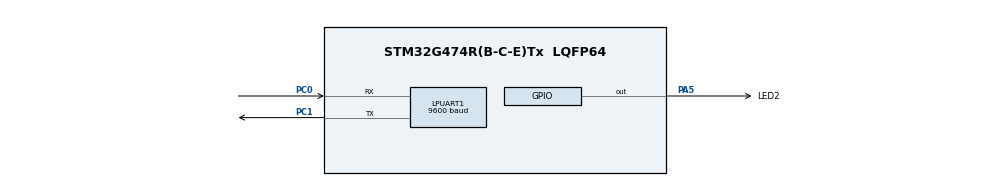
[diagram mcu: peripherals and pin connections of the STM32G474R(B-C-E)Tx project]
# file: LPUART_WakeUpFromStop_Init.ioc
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LPUART1.BaudRate=9600
LPUART1.ClockPrescaler=UART_PRESCALER_DIV1
LPUART1.DMADisableonRxErrorParam=UART_ADVFEATURE_DMA_ENABLEONRXERROR
LPUART1.DataInvertParam=UART_ADVFEATURE_DATAINV_DISABLE
LPUART1.FIFOMode=UART_FIFOMODE_DISABLE
LPUART1.MSBFirstParam=UART_ADVFEATURE_MSBFIRST_DISABLE
LPUART1.Mode=UART_MODE_TX_RX
LPUART1.OneBitSampling=UART_ONE_BIT_SAMPLE_DISABLE
LPUART1.OverrunDisableParam=UART_ADVFEATURE_OVERRUN_ENABLE
LPUART1.Parity=UART_PARITY_NONE
LPUART1.RXFIFOThreshold=UART_RXFIFO_THRESHOLD_1_8
LPUART1.RxPinLevelInvertParam=UART_ADVFEATURE_RXINV_DISABLE
LPUART1.StopBits=UART_STOPBITS_1
LPUART1.SwapParam=UART_ADVFEATURE_SWAP_DISABLE
LPUART1.TXFIFOThreshold=UART_TXFIFO_THRESHOLD_1_8
LPUART1.TxPinLevelInvertParam=UART_ADVFEATURE_TXINV_DISABLE
LPUART1.WordLength=UART_WORDLENGTH_8B
Mcu.Family=STM32G4
Mcu.Name=STM32G474R(B-C-E)Tx
Mcu.Package=LQFP64
NVIC.LPUART1_IRQn=true\:0\:0\:false\:false\:true\:true\:true\:true
NVIC.PriorityGroup=NVIC_PRIORITYGROUP_4
PA5.GPIO_Label=LED2
PA5.Signal=GPIO_Output
PC0.GPIO_Speed=GPIO_SPEED_FREQ_HIGH
PC0.Mode=Asynchronous
PC0.Signal=LPUART1_RX
PC1.GPIO_Speed=GPIO_SPEED_FREQ_HIGH
PC1.Mode=Asynchronous
PC1.Signal=LPUART1_TX
ProjectManager.HeapSize=0x200
ProjectManager.StackSize=0x400
ProjectManager.TargetToolchain=EWARM V8.32
RCC.ADC12Freq_Value=16000000
RCC.ADC345Freq_Value=16000000
RCC.AHBFreq_Value=16000000
RCC.APB1Freq_Value=16000000
RCC.APB1TimFreq_Value=16000000
RCC.APB2Freq_Value=16000000
RCC.APB2TimFreq_Value=16000000
RCC.CortexFreq_Value=16000000
RCC.EXTERNAL_CLOCK_VALUE=12288000
RCC.HCLKFreq_Value=16000000
RCC.HSE_VALUE=24000000
RCC.HSI48_VALUE=48000000
RCC.HSI_VALUE=16000000
RCC.LPUART1CLockSelection=RCC_LPUART1CLKSOURCE_HSI
RCC.LSE_VALUE=32768
RCC.PLLM=RCC_PLLM_DIV4
RCC.PLLN=85
RCC.SYSCLKFreq_VALUE=16000000
RCC.UART4CLockSelection=RCC_UART4CLKSOURCE_HSI
RCC.UART5CLockSelection=RCC_UART5CLKSOURCE_HSI
RCC.USART1CLockSelection=RCC_USART1CLKSOURCE_HSI
RCC.USART2CLockSelection=RCC_USART2CLKSOURCE_HSI
RCC.USART3CLockSelection=RCC_USART3CLKSOURCE_HSI
RCC.USBFreq_Value=170000000
RCC.VCOOutputFreq_Value=340000000
VP_SYS_VS_DBSignals.Mode=DisableDeadBatterySignals
board=custom

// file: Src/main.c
/* USER CODE BEGIN Header */
/**
  ******************************************************************************
  * @file    Examples_LL/LPUART/LPUART_WakeUpFromStop_Init/Src/main.c
  * @author  MCD Application Team
  * @brief   This example describes how to configure LPUART peripheral in Asynchronous mode
  *          for being able to wake from Stop 0 mode when a character is received on RX line using
  *          the STM32G4xx LPUART LL API.
  *          Peripheral initialization done using LL initialization function.
  ******************************************************************************
  * @attention
  *
  * Copyright (c) 2019 STMicroelectronics.
  * All rights reserved.
  *
  * This software is licensed under terms that can be found in the LICENSE file
  * in the root directory of this software component.
  * If no LICENSE file comes with this software, it is provided AS-IS.
  *
  ******************************************************************************
  */
/* USER CODE END Header */
#include "main.h"

/* USER CODE BEGIN PV */
/**
  * @brief Variables used for character reception from PC Com port
  */
__IO uint8_t      ubFinalCharReceived = 0;
__IO uint32_t     ubReceivedChar;

/**
  * @brief Text string printed on PC Com port to inform MCU will enter in Stop 0 Mode
  */
uint8_t aTextInfo[] = "\r\nLPUART Example : MCU will now enter in Stop 0 mode.\n\rEnter any character for waking up MCU.\r\n";
/* USER CODE END PV */

void SystemClock_Config(void);
static void MX_GPIO_Init(void);
static void MX_LPUART1_UART_Init(void);
/* USER CODE BEGIN PFP */
void     LED_On(void);
void     LED_Off(void);
void     LED_Blinking(uint32_t Period);
void     LED_Blinking_3s(void);
void     Configure_PWR(void);
void     PrepareLPUARTToStopMode(void);
void     EnterSTOP0Mode(void);
void     PrintInfo(void);
/* USER CODE END PFP */

int main(void)
{

  /* MCU Configuration--------------------------------------------------------*/

  /* Reset of all peripherals, Initializes the Flash interface and the Systick. */

  LL_APB2_GRP1_EnableClock(LL_APB2_GRP1_PERIPH_SYSCFG);
  LL_APB1_GRP1_EnableClock(LL_APB1_GRP1_PERIPH_PWR);

  NVIC_SetPriorityGrouping(NVIC_PRIORITYGROUP_4);

  /* System interrupt init*/

  /** Disable the internal Pull-Up in Dead Battery pins of UCPD peripheral
  */
  LL_PWR_DisableUCPDDeadBattery();

  /* Configure the system clock */
  SystemClock_Config();

  /* Initialize all configured peripherals */
  MX_GPIO_Init();
  MX_LPUART1_UART_Init();
  /* USER CODE BEGIN 2 */

  /* Configure Power IP */
  Configure_PWR();

  /* Start main program loop :
     - make LED blink during 3 sec
     - Enter Stop 0 mode (LED turned Off)
     - Wait for any character received on LPUART RX line for waking up MCU
  */
  while (ubFinalCharReceived == 0)
  {
    /* LED blinks during 3 seconds */
    LED_Blinking_3s();

    /* Send Text Information on LPUART TX to PC Com port */
    PrintInfo();

    /* Prepare LPUART for entering Stop Mode */
    PrepareLPUARTToStopMode();

    /* Enter Stop 0 mode */
    EnterSTOP0Mode();

    /* At this point, MCU just wakes up from Stop 0 mode */
  }
  /* USER CODE END 2 */

  /* Infinite loop */
  while (1)
  {

  }
}

void SystemClock_Config(void)
{
  LL_FLASH_SetLatency(LL_FLASH_LATENCY_0);
  while(LL_FLASH_GetLatency() != LL_FLASH_LATENCY_0)
  {
  }
  LL_PWR_SetRegulVoltageScaling(LL_PWR_REGU_VOLTAGE_SCALE1);
  LL_RCC_HSI_Enable();
   /* Wait till HSI is ready */
  while(LL_RCC_HSI_IsReady() != 1)
  {
  }

  LL_RCC_HSI_SetCalibTrimming(64);
  LL_RCC_SetSysClkSource(LL_RCC_SYS_CLKSOURCE_HSI);
   /* Wait till System clock is ready */
  while(LL_RCC_GetSysClkSource() != LL_RCC_SYS_CLKSOURCE_STATUS_HSI)
  {
  }

  /* Set AHB prescaler*/
  LL_RCC_SetAHBPrescaler(LL_RCC_SYSCLK_DIV_1);
  LL_RCC_SetAPB1Prescaler(LL_RCC_APB1_DIV_1);
  LL_RCC_SetAPB2Prescaler(LL_RCC_APB2_DIV_1);

  LL_Init1msTick(16000000);

  LL_SetSystemCoreClock(16000000);
}

static void MX_LPUART1_UART_Init(void)
{

  LL_LPUART_InitTypeDef LPUART_InitStruct = {0};

  LL_GPIO_InitTypeDef GPIO_InitStruct = {0};

  LL_RCC_SetLPUARTClockSource(LL_RCC_LPUART1_CLKSOURCE_HSI);

  /* Peripheral clock enable */
  LL_APB1_GRP2_EnableClock(LL_APB1_GRP2_PERIPH_LPUART1);

  LL_AHB2_GRP1_EnableClock(LL_AHB2_GRP1_PERIPH_GPIOC);
  /**LPUART1 GPIO Configuration
  PC0   ------> LPUART1_RX
  PC1   ------> LPUART1_TX
  */
  GPIO_InitStruct.Pin = LL_GPIO_PIN_0;
  GPIO_InitStruct.Mode = LL_GPIO_MODE_ALTERNATE;
  GPIO_InitStruct.Speed = LL_GPIO_SPEED_FREQ_HIGH;
  GPIO_InitStruct.OutputType = LL_GPIO_OUTPUT_PUSHPULL;
  GPIO_InitStruct.Pull = LL_GPIO_PULL_NO;
  GPIO_InitStruct.Alternate = LL_GPIO_AF_8;
  LL_GPIO_Init(GPIOC, &GPIO_InitStruct);

  GPIO_InitStruct.Pin = LL_GPIO_PIN_1;
  GPIO_InitStruct.Mode = LL_GPIO_MODE_ALTERNATE;
  GPIO_InitStruct.Speed = LL_GPIO_SPEED_FREQ_HIGH;
  GPIO_InitStruct.OutputType = LL_GPIO_OUTPUT_PUSHPULL;
  GPIO_InitStruct.Pull = LL_GPIO_PULL_NO;
  GPIO_InitStruct.Alternate = LL_GPIO_AF_8;
  LL_GPIO_Init(GPIOC, &GPIO_InitStruct);

  /* LPUART1 interrupt Init */
  NVIC_SetPriority(LPUART1_IRQn, NVIC_EncodePriority(NVIC_GetPriorityGrouping(),0, 0));
  NVIC_EnableIRQ(LPUART1_IRQn);

  /* USER CODE BEGIN LPUART1_Init 1 */

  /* Set LPUART1 clock source as HSI */
  LL_RCC_SetLPUARTClockSource(LL_RCC_LPUART1_CLKSOURCE_HSI);

  /* USER CODE END LPUART1_Init 1 */
  LPUART_InitStruct.PrescalerValue = LL_LPUART_PRESCALER_DIV1;
  LPUART_InitStruct.BaudRate = 9600;
  LPUART_InitStruct.DataWidth = LL_LPUART_DATAWIDTH_8B;
  LPUART_InitStruct.StopBits = LL_LPUART_STOPBITS_1;
  LPUART_InitStruct.Parity = LL_LPUART_PARITY_NONE;
  LPUART_InitStruct.TransferDirection = LL_LPUART_DIRECTION_TX_RX;
  LPUART_InitStruct.HardwareFlowControl = LL_LPUART_HWCONTROL_NONE;
  LL_LPUART_Init(LPUART1, &LPUART_InitStruct);
  LL_LPUART_SetTXFIFOThreshold(LPUART1, LL_LPUART_FIFOTHRESHOLD_1_8);
  LL_LPUART_SetRXFIFOThreshold(LPUART1, LL_LPUART_FIFOTHRESHOLD_1_8);
  LL_LPUART_DisableFIFO(LPUART1);

  /* USER CODE BEGIN WKUPType LPUART1 */

  /* Set the wake-up event type : specify wake-up on RXNE flag */
  LL_LPUART_SetWKUPType(LPUART1, LL_LPUART_WAKEUP_ON_RXNE);

  /* USER CODE END WKUPType LPUART1 */

  LL_LPUART_Enable(LPUART1);

  /* Polling LPUART1 initialisation */
  while((!(LL_LPUART_IsActiveFlag_TEACK(LPUART1))) || (!(LL_LPUART_IsActiveFlag_REACK(LPUART1))))
  {
  }

}

static void MX_GPIO_Init(void)
{
  LL_GPIO_InitTypeDef GPIO_InitStruct = {0};

  /* GPIO Ports Clock Enable */
  LL_AHB2_GRP1_EnableClock(LL_AHB2_GRP1_PERIPH_GPIOC);
  LL_AHB2_GRP1_EnableClock(LL_AHB2_GRP1_PERIPH_GPIOA);

  /**/
  LL_GPIO_ResetOutputPin(LED2_GPIO_Port, LED2_Pin);

  /**/
  GPIO_InitStruct.Pin = LED2_Pin;
  GPIO_InitStruct.Mode = LL_GPIO_MODE_OUTPUT;
  GPIO_InitStruct.Speed = LL_GPIO_SPEED_FREQ_LOW;
  GPIO_InitStruct.OutputType = LL_GPIO_OUTPUT_PUSHPULL;
  GPIO_InitStruct.Pull = LL_GPIO_PULL_NO;
  LL_GPIO_Init(LED2_GPIO_Port, &GPIO_InitStruct);

}

/* USER CODE BEGIN 4 */
/**
  * @brief  Function to configure and initialize PWR IP.
  * @param  None
  * @retval None
  */
void Configure_PWR(void)
{
  /* Enable Power Clock */
  LL_APB1_GRP1_EnableClock(LL_APB1_GRP1_PERIPH_PWR);

}

/**
  * @brief  Function to configure LPUART for being ready to enter "Stop 0" mode.
  * @param  None
  * @retval None
  */
void PrepareLPUARTToStopMode(void)
{

  /* Empty RX Fifo before entering Stop mode (Otherwise, characters already present in FIFO
     will lead to immediate wake up */
  while (LL_LPUART_IsActiveFlag_RXNE(LPUART1))
  {
    /* Read Received character. RXNE flag is cleared by reading of RDR register */
    ubReceivedChar = LL_LPUART_ReceiveData8(LPUART1);
  }

  /* Clear OVERRUN flag */
  LL_LPUART_ClearFlag_ORE(LPUART1);

  /* Make sure that no LPUART transfer is on-going */
  while (LL_LPUART_IsActiveFlag_BUSY(LPUART1) == 1)
  {
  }
  /* Make sure that LPUART is ready to receive */
  while (LL_LPUART_IsActiveFlag_REACK(LPUART1) == 0)
  {
  }

  /* About to enter stop mode: switch off LED */
  LED_Off();

  /* Configure LPUART1 transfer interrupts : */
  /* Clear WUF flag and enable the UART Wake Up from stop mode Interrupt */
  LL_LPUART_ClearFlag_WKUP(LPUART1);
  LL_LPUART_EnableIT_WKUP(LPUART1);

  /* Enable Wake Up From Stop */
  LL_LPUART_EnableInStopMode(LPUART1);
}

/**
  * @brief  Function to enter in "Stop 0" mode.
  * @param  None
  * @retval None
  */
void EnterSTOP0Mode(void)
{
  /** Request to enter "Stop 0" mode
    * Following procedure describe in STM32G4xx Reference Manual
    * See PWR part, section Low-power modes, "Stop 0" mode
    */
  /* Set Stop 0 mode when CPU enters deepsleep */
  LL_PWR_SetPowerMode(LL_PWR_MODE_STOP0);

  /* Set SLEEPDEEP bit of Cortex System Control Register */
  LL_LPM_EnableDeepSleep();

  /* Request Wait For Interrupt */
  __WFI();
}

/**
  * @brief  Send Txt information message on LPUART Tx line (to PC Com port).
  * @param  None
  * @retval None
  */
void PrintInfo(void)
{
  uint32_t index = 0;

  /* Send characters one per one, until last char to be sent */
  for (index = 0; index < sizeof(aTextInfo); index++)
  {
    /* Wait for TXE flag to be raised */
    while (!LL_LPUART_IsActiveFlag_TXE(LPUART1))
    {
    }

    /* Write character in Transmit Data register.
       TXE flag is cleared by writing data in TDR register */
    LL_LPUART_TransmitData8(LPUART1, aTextInfo[index]);
  }

  /* Wait for TC flag to be raised for last char */
  while (!LL_LPUART_IsActiveFlag_TC(LPUART1))
  {
  }
}

/**
  * @brief  Turn-on LED2.
  * @param  None
  * @retval None
  */
void LED_On(void)
{
  /* Turn LED2 on */
  LL_GPIO_SetOutputPin(LED2_GPIO_Port, LED2_Pin);
}

/**
  * @brief  Turn-off LED2.
  * @param  None
  * @retval None
  */
void LED_Off(void)
{
  /* Turn LED2 off */
  LL_GPIO_ResetOutputPin(LED2_GPIO_Port, LED2_Pin);
}

/**
  * @brief  Set LED2 to Blinking mode for an infinite loop (toggle period based on value provided as input parameter).
  * @param  Period : Period of time (in ms) between each toggling of LED
  *   This parameter can be user defined values. Pre-defined values used in that example are :
  *     @arg LED_BLINK_FAST : Fast Blinking
  *     @arg LED_BLINK_SLOW : Slow Blinking
  *     @arg LED_BLINK_ERROR : Error specific Blinking
  * @retval None
  */
void LED_Blinking(uint32_t Period)
{
  /* Toggle IO in an infinite loop */
  while (1)
  {
    LL_GPIO_TogglePin(LED2_GPIO_Port, LED2_Pin);
    LL_mDelay(Period);
  }
}

/**
  * @brief  Set LED2 to Blinking mode during 3s.
  * @param  None
  * @retval None
  */
void LED_Blinking_3s(void)
{
  uint32_t index = 0;

  /* Toggle IO in during 3s (15*200ms) */
  for (index = 0; index < 15; index++)
  {
    LL_GPIO_TogglePin(LED2_GPIO_Port, LED2_Pin);
    LL_mDelay(200);
  }
}

/******************************************************************************/
/*   IRQ HANDLER TREATMENT Functions                                          */
/******************************************************************************/

/**
  * @brief  Function called from LPUART IRQ Handler when RXNE flag is set
  *         Function is in charge of reading character received on LPUART RX line.
  * @param  None
  * @retval None
  */
void LPUART_CharReception_Callback(void)
{
  /* Read Received character. RXNE flag is cleared by reading of RDR register */
  ubReceivedChar = LL_LPUART_ReceiveData8(LPUART1);

  /* Check if received value is corresponding to specific one : S or s */
  if ((ubReceivedChar == 'S') || (ubReceivedChar == 's'))
  {
    /* Turn LED2 On : Expected character has been received */
    LED_On();

    /* End of program : set boolean for main loop exit */
    ubFinalCharReceived = 1;
  }

  /* Echo received character on TX */
  LL_LPUART_TransmitData8(LPUART1, ubReceivedChar);
}

/**
  * @brief  Function called in case of error detected in LPUART IT Handler
  * @param  None
  * @retval None
  */
void Error_Callback(void)
{
  /* Disable LPUART1_IRQn */
  NVIC_DisableIRQ(LPUART1_IRQn);

  /* Unexpected event : Set LED2 to Blinking mode to indicate error occurs */
  LED_Blinking(LED_BLINK_ERROR);
}

/* USER CODE END 4 */

void Error_Handler(void)
{
}
